VERSION ""

NS_ :

BS_:

BU_: Vector__XXX

BO_ 100 FSM_STARTUP: 0 FSM

BO_ 101 FSM_ERRORS: 8 FSM
SG_ papps_out_of_range : 0|1@1+ (1,0) [0|1] "" Vector__XXX
SG_ sapps_out_of_range : 1|1@1+ (1,0) [0|1] "" Vector__XXX

BO_ 102 FSM_CAN_TX_FIFO_OVERFLOW: 4 FSM
SG_ overflow_count : 0|32@1+ (1,0) [0|4294967295] "" Vector__XXX

BO_ 103 FSM_CAN_RX_FIFO_OVERFLOW: 4 FSM
SG_ overflow_count : 0|32@1+ (1,0) [0|4294967295] "" Vector__XXX

BO_ 104 FSM_HEARTBEAT: 1 FSM
SG_ DUMMY_VARIABLE : 0|1@1+ (1,0) [0|1] "" BMS

BO_ 200 BMS_STARTUP: 0 BMS

BO_ 201 BMS_ERRORS: 8 BMS
SG_ DUMMY_VARIABLE : 0|1@1+ (1,0) [0|1] "" Vector__XXX

BO_ 202 BMS_CAN_TX_FIFO_OVERFLOW: 4 BMS
SG_ overflow_count : 0|32@1+ (1,0) [0|1] "" Vector__XXX

BO_ 203 BMS_CAN_RX_FIFO_OVERFLOW: 4 BMS
SG_ overflow_count : 0|32@1+ (1,0) [0|1] "" Vector__XXX

BO_ 204 BMS_HEARTBEAT: 1 BMS
SG_ DUMMY_VARIABLE : 0|1@1+ (1,0) [0|1] "" FSM,DCM,PDM

BO_ 300 PDM_STARTUP: 0 PDM

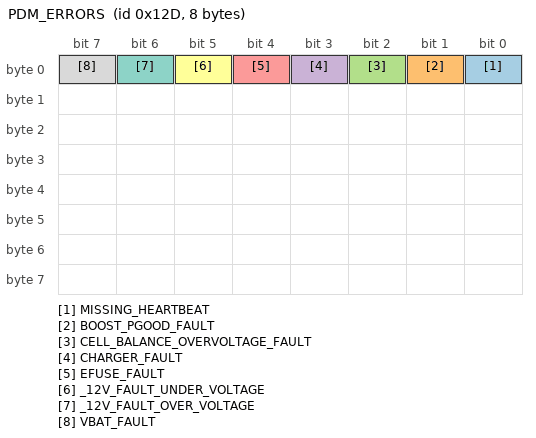
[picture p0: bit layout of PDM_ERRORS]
BO_ 301 PDM_ERRORS: 8 PDM
SG_ MISSING_HEARTBEAT : 0|1@1+ (1,0) [0|1] "" Vector__XXX
SG_ BOOST_PGOOD_FAULT : 1|1@1+ (1,0) [0|1] "" Vector__XXX
SG_ CELL_BALANCE_OVERVOLTAGE_FAULT : 2|1@1+ (1,0) [0|1] "" Vector__XXX
SG_ CHARGER_FAULT : 3|1@1+ (1,0) [0|1] "" Vector__XXX
SG_ EFUSE_FAULT : 4|1@1+ (1,0) [0|1] "" Vector__XXX
SG_ _12V_FAULT_UNDER_VOLTAGE : 5|1@1+ (1,0) [0|1] "" Vector__XXX
SG_ _12V_FAULT_OVER_VOLTAGE : 6|1@1+ (1,0) [0|1] "" Vector__XXX
SG_ VBAT_FAULT : 7|1@1+ (1,0) [0|1] "" Vector__XXX

BO_ 302 PDM_CAN_TX_FIFO_OVERFLOW: 4 PDM
SG_ overflow_count : 0|32@1+ (1,0) [0|1] "" Vector__XXX

BO_ 303 PDM_CAN_RX_FIFO_OVERFLOW: 4 PDM
SG_ overflow_count : 0|32@1+ (1,0) [0|1] "" Vector__XXX

BO_ 304 PDM_HEARTBEAT: 1 PDM
SG_ DUMMY_VARIABLE : 0|1@1+ (1,0) [0|1] "" BMS

BO_ 305 PDM_AUX1_AUX2_CURRENT: 8 PDM
SG_ Auxiliary1_Current : 0|32@1- (1,0) [-3.4E038|3.4E038] "A" Vector__XXX
SG_ Auxiliary2_Current : 32|32@1- (1,0) [-3.4E038|3.4E038] "A" Vector__XXX

BO_ 306 PDM_COOLING_PDMFAN_CURRENT: 8 PDM
SG_ Cooling_Pump_Current : 0|32@1- (1,0) [-3.4E038|3.4E038] "A" Vector__XXX
SG_ PDM_Enclosure_Fan_Current : 32|32@1- (1,0) [-3.4E038|3.4E038] "A" Vector__XXX

BO_ 307 PDM_AIRSHDN_CANGLV_CURRENT: 8 PDM
SG_ AIR_Shutdown_Current : 0|32@1- (1,0) [-3.4E038|3.4E038] "A" Vector__XXX
SG_ Grounded_Low_Voltage_Current : 32|32@1- (1,0) [-3.4E038|3.4E038] "A" Vector__XXX

BO_ 308 PDM_ACCUMULATOR_FAN_CURRENT: 8 PDM
SG_ Accumulator_Segment_Fan_Current : 0|32@1- (1,0) [-3.4E038|3.4E038] "A" Vector__XXX
SG_ Accumulator_Enc_Fan_Current : 32|32@1- (1,0) [-3.4E038|3.4E038] "A" Vector__XXX

BO_ 309 PDM_INVERTER_IO_CURRENT: 8 PDM
SG_ Left_Inverter_GPIOs_Current : 0|32@1- (1,0) [-3.4E038|3.4E038] "A" Vector__XXX
SG_ Right_Inverter_GPIOs_Current : 32|32@1- (1,0) [-3.4E038|3.4E038] "A" Vector__XXX

BO_ 310 PDM_GLV_VBAT: 8 PDM
SG_ GLV : 0|32@1- (1,0) [-3.4E038|3.4E038] "V" Vector__XXX
SG_ VBAT : 32|32@1- (1,0) [-3.4E038|3.4E038] "V" Vector__XXX

BO_ 311 PDM_FLYWIRE: 4 PDM
SG_ FLYWIRE : 0|32@1- (1,0) [-3.4E038|3.4E038] "V" Vector__XXX

BO_ 400 DCM_STARTUP: 0 DCM

BO_ 401 DCM_ERRORS: 8 DCM
SG_ DUMMY_VARIABLE : 0|1@1+ (1,0) [0|1] "" Vector__XXX

BO_ 402 DCM_CAN_TX_FIFO_OVERFLOW: 4 DCM
SG_ overflow_count : 0|32@1+ (1,0) [0|1] "" Vector__XXX

BO_ 403 DCM_CAN_RX_FIFO_OVERFLOW: 4 DCM
SG_ overflow_count : 0|32@1+ (1,0) [0|1] "" Vector__XXX

BO_ 404 DCM_HEARTBEAT: 1 DCM
SG_ DUMMY_VARIABLE : 0|1@1+ (1,0) [0|1] "" BMS

CM_ BO_ 100 "Sent out by the FSM when it starts up";
CM_ BO_ 101 "This message contains a bit for each error that the FSM might throw";
CM_ BO_ 304 "TODO: descriptive comment";
CM_ BO_ 305 "Indicates that we tried to transmit messages faster then we can send them, so our internal FIFO queue overflowed";
CM_ BO_ 305 "This message indicates the current being drawn by the auxiliary 1 and 2 outputs";
CM_ BO_ 306 "This message indicates the current being drawn by the cooling pump and PDM enclosure fan";
CM_ BO_ 307 "This message indicates the current being drawn by the AIR shutdown circuit and the 12V Grounded-Low-Voltage (GLV) system";
CM_ BO_ 308 "This message indicates the current being drawn by the fans on the accumulator";
CM_ BO_ 309 "This message indicates the current being drawn by the left and right BAMOCAR D3 controller";
CM_ BO_ 310 "This message indicates the voltage sense for the 12V Grounded Low Voltage (GLV) system and the two on-board 18650s";
CM_ BO_ 311 "The message indicates the voltage sense for the Vicor 12V output";
CM_ BO_ 98 "Indicates that we tried to transmit messages faster then we can send them, so our internal FIFO queue overflowed";
CM_ SG_ 305 Auxiliary1_Current "This variable indicates the current being drawn by the auxiliary 1 output";
CM_ SG_ 305 Auxiliary2_Current "This variable indicates the current being drawn by the auxiliary 2 output";
CM_ SG_ 306 Cooling_Pump_Current "This variable indicates the current being drawn by the cooling pump";
CM_ SG_ 306 PDM_Enclosure_Fan_Current "This variable indicates the current being drawn by the fan on the PDM enclosure";
CM_ SG_ 307 AIR_Shutdown_Current "This variable indicates the current being drawn by the AIR shutdown circuit";
CM_ SG_ 307 Grounded_Low_Voltage_Current "This variable indicates the current being drawn by the 12V Grounded-Low-Voltage (GLV) system";
CM_ SG_ 308 Accumulator_Enc_Fan_Current "This variable indicates the current being drawn by the fans on the accumulator enclosure";
CM_ SG_ 308 Accumulator_Segment_Fan_Current "This variable indicates the current being drawn by the fans on the accumulator segments";
CM_ SG_ 309 Left_Inverter_GPIOs_Current "This variable indicates the current being drawn by the left BAMOCAR D3 controller";
CM_ SG_ 309 Right_Inverter_GPIOs_Current "This variable indicates the current being drawn by the right BAMOCAR D3 controller";
CM_ SG_ 310 GLV "This variable indicates the voltage sense for the 12V powering the Grounded Low Voltage (GLV) system";
CM_ SG_ 310 VBAT "This variable indicates the the voltage sense for the two on-board 18650s";
CM_ SG_ 311 FLYWIRE "The variable indicates the voltage sense for the Vicor 12V output";

BA_DEF_  "BusType" STRING ;
BA_DEF_ BO_  "GenMsgCycleTime" INT 0 65535;

BA_DEF_DEF_  "BusType" "CAN";
BA_DEF_DEF_  "GenMsgCycleTime" 0;

BA_ "GenMsgCycleTime" BO_ 101 1000;
BA_ "GenMsgCycleTime" BO_ 104 100;
BA_ "GenMsgCycleTime" BO_ 201 100;
BA_ "GenMsgCycleTime" BO_ 204 100;
BA_ "GenMsgCycleTime" BO_ 301 1000;
BA_ "GenMsgCycleTime" BO_ 304 100;
BA_ "GenMsgCycleTime" BO_ 306 1000;
BA_ "GenMsgCycleTime" BO_ 307 100;
BA_ "GenMsgCycleTime" BO_ 308 1000;
BA_ "GenMsgCycleTime" BO_ 309 1000;
BA_ "GenMsgCycleTime" BO_ 310 1000;
BA_ "GenMsgCycleTime" BO_ 311 1000;
BA_ "GenMsgCycleTime" BO_ 404 100;

SIG_VALTYPE_ 102 Auxiliary1_Current : 1;
SIG_VALTYPE_ 102 Auxiliary2_Current : 1;
SIG_VALTYPE_ 306 Cooling_Pump_Current : 1;
SIG_VALTYPE_ 306 PDM_Enclosure_Fan_Current : 1;
SIG_VALTYPE_ 307 AIR_Shutdown_Current : 1;
SIG_VALTYPE_ 307 Grounded_Low_Voltage_Current : 1;
SIG_VALTYPE_ 308 Accumulator_Enc_Fan_Current : 1;
SIG_VALTYPE_ 308 Accumulator_Segment_Fan_Current : 1;
SIG_VALTYPE_ 309 Left_Inverter_GPIOs_Current : 1;
SIG_VALTYPE_ 309 Right_Inverter_GPIOs_Current : 1;
SIG_VALTYPE_ 310 GLV : 1;
SIG_VALTYPE_ 310 VBAT : 1;
SIG_VALTYPE_ 311 FLYWIRE : 1;
